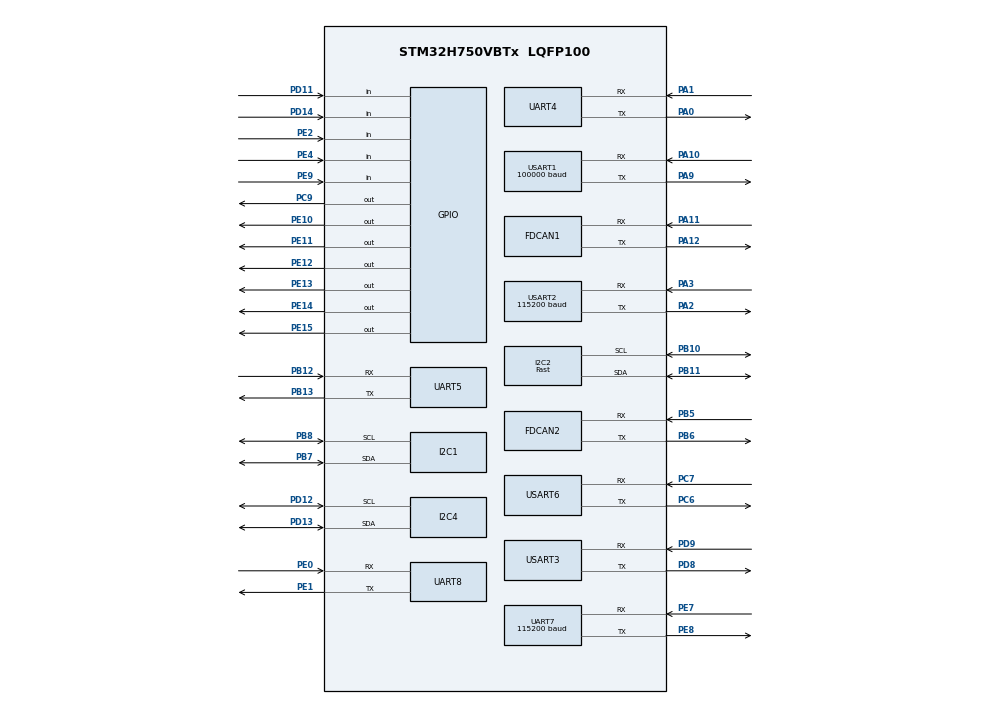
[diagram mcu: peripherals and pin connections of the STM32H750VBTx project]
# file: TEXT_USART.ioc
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Dma.Request0=USART1_RX
Dma.Request1=USART1_TX
Dma.Request10=UART7_RX
Dma.Request11=UART7_TX
Dma.Request12=UART8_RX
Dma.Request13=UART8_TX
Dma.Request14=USART6_TX
Dma.Request15=USART6_RX
Dma.Request2=USART2_RX
Dma.Request3=USART2_TX
Dma.Request4=USART3_RX
Dma.Request5=USART3_TX
Dma.Request6=UART4_RX
Dma.Request7=UART4_TX
Dma.Request8=UART5_RX
Dma.Request9=UART5_TX
Dma.UART4_RX.6.Direction=DMA_PERIPH_TO_MEMORY
Dma.UART4_RX.6.EventEnable=DISABLE
Dma.UART4_RX.6.FIFOMode=DMA_FIFOMODE_DISABLE
Dma.UART4_RX.6.Instance=DMA2_Stream0
Dma.UART4_RX.6.MemDataAlignment=DMA_MDATAALIGN_BYTE
Dma.UART4_RX.6.MemInc=DMA_MINC_ENABLE
Dma.UART4_RX.6.Mode=DMA_NORMAL
Dma.UART4_RX.6.PeriphDataAlignment=DMA_PDATAALIGN_BYTE
Dma.UART4_RX.6.PeriphInc=DMA_PINC_DISABLE
Dma.UART4_RX.6.Polarity=HAL_DMAMUX_REQ_GEN_RISING
Dma.UART4_RX.6.Priority=DMA_PRIORITY_LOW
Dma.UART4_RX.6.RequestNumber=1
Dma.UART4_RX.6.SignalID=NONE
Dma.UART4_RX.6.SyncEnable=DISABLE
Dma.UART4_RX.6.SyncPolarity=HAL_DMAMUX_SYNC_NO_EVENT
Dma.UART4_RX.6.SyncRequestNumber=1
Dma.UART4_RX.6.SyncSignalID=NONE
Dma.UART4_TX.7.Direction=DMA_MEMORY_TO_PERIPH
Dma.UART4_TX.7.EventEnable=DISABLE
Dma.UART4_TX.7.FIFOMode=DMA_FIFOMODE_DISABLE
Dma.UART4_TX.7.Instance=DMA2_Stream1
Dma.UART4_TX.7.MemDataAlignment=DMA_MDATAALIGN_BYTE
Dma.UART4_TX.7.MemInc=DMA_MINC_ENABLE
Dma.UART4_TX.7.Mode=DMA_NORMAL
Dma.UART4_TX.7.PeriphDataAlignment=DMA_PDATAALIGN_BYTE
Dma.UART4_TX.7.PeriphInc=DMA_PINC_DISABLE
Dma.UART4_TX.7.Polarity=HAL_DMAMUX_REQ_GEN_RISING
Dma.UART4_TX.7.Priority=DMA_PRIORITY_LOW
Dma.UART4_TX.7.RequestNumber=1
Dma.UART4_TX.7.SignalID=NONE
Dma.UART4_TX.7.SyncEnable=DISABLE
Dma.UART4_TX.7.SyncPolarity=HAL_DMAMUX_SYNC_NO_EVENT
Dma.UART4_TX.7.SyncRequestNumber=1
Dma.UART4_TX.7.SyncSignalID=NONE
Dma.UART5_RX.8.Direction=DMA_PERIPH_TO_MEMORY
Dma.UART5_RX.8.EventEnable=DISABLE
Dma.UART5_RX.8.FIFOMode=DMA_FIFOMODE_DISABLE
Dma.UART5_RX.8.Instance=DMA2_Stream3
Dma.UART5_RX.8.MemDataAlignment=DMA_MDATAALIGN_BYTE
Dma.UART5_RX.8.MemInc=DMA_MINC_ENABLE
Dma.UART5_RX.8.Mode=DMA_NORMAL
Dma.UART5_RX.8.PeriphDataAlignment=DMA_PDATAALIGN_BYTE
Dma.UART5_RX.8.PeriphInc=DMA_PINC_DISABLE
Dma.UART5_RX.8.Polarity=HAL_DMAMUX_REQ_GEN_RISING
Dma.UART5_RX.8.Priority=DMA_PRIORITY_LOW
Dma.UART5_RX.8.RequestNumber=1
Dma.UART5_RX.8.SignalID=NONE
Dma.UART5_RX.8.SyncEnable=DISABLE
Dma.UART5_RX.8.SyncPolarity=HAL_DMAMUX_SYNC_NO_EVENT
Dma.UART5_RX.8.SyncRequestNumber=1
Dma.UART5_RX.8.SyncSignalID=NONE
Dma.UART5_TX.9.Direction=DMA_MEMORY_TO_PERIPH
Dma.UART5_TX.9.EventEnable=DISABLE
Dma.UART5_TX.9.FIFOMode=DMA_FIFOMODE_DISABLE
Dma.UART5_TX.9.Instance=DMA2_Stream4
Dma.UART5_TX.9.MemDataAlignment=DMA_MDATAALIGN_BYTE
Dma.UART5_TX.9.MemInc=DMA_MINC_ENABLE
Dma.UART5_TX.9.Mode=DMA_NORMAL
Dma.UART5_TX.9.PeriphDataAlignment=DMA_PDATAALIGN_BYTE
Dma.UART5_TX.9.PeriphInc=DMA_PINC_DISABLE
Dma.UART5_TX.9.Polarity=HAL_DMAMUX_REQ_GEN_RISING
Dma.UART5_TX.9.Priority=DMA_PRIORITY_LOW
Dma.UART5_TX.9.RequestNumber=1
Dma.UART5_TX.9.SignalID=NONE
Dma.UART5_TX.9.SyncEnable=DISABLE
Dma.UART5_TX.9.SyncPolarity=HAL_DMAMUX_SYNC_NO_EVENT
Dma.UART5_TX.9.SyncRequestNumber=1
Dma.UART5_TX.9.SyncSignalID=NONE
Dma.UART7_RX.10.Direction=DMA_PERIPH_TO_MEMORY
Dma.UART7_RX.10.EventEnable=DISABLE
Dma.UART7_RX.10.FIFOMode=DMA_FIFOMODE_DISABLE
Dma.UART7_RX.10.Instance=DMA2_Stream6
Dma.UART7_RX.10.MemDataAlignment=DMA_MDATAALIGN_BYTE
Dma.UART7_RX.10.MemInc=DMA_MINC_ENABLE
Dma.UART7_RX.10.Mode=DMA_NORMAL
Dma.UART7_RX.10.PeriphDataAlignment=DMA_PDATAALIGN_BYTE
Dma.UART7_RX.10.PeriphInc=DMA_PINC_DISABLE
Dma.UART7_RX.10.Polarity=HAL_DMAMUX_REQ_GEN_RISING
Dma.UART7_RX.10.Priority=DMA_PRIORITY_LOW
Dma.UART7_RX.10.RequestNumber=1
Dma.UART7_RX.10.SignalID=NONE
Dma.UART7_RX.10.SyncEnable=DISABLE
Dma.UART7_RX.10.SyncPolarity=HAL_DMAMUX_SYNC_NO_EVENT
Dma.UART7_RX.10.SyncRequestNumber=1
Dma.UART7_RX.10.SyncSignalID=NONE
Dma.UART7_TX.11.Direction=DMA_MEMORY_TO_PERIPH
Dma.UART7_TX.11.EventEnable=DISABLE
Dma.UART7_TX.11.FIFOMode=DMA_FIFOMODE_DISABLE
Dma.UART7_TX.11.Instance=DMA2_Stream2
Dma.UART7_TX.11.MemDataAlignment=DMA_MDATAALIGN_BYTE
Dma.UART7_TX.11.MemInc=DMA_MINC_ENABLE
Dma.UART7_TX.11.Mode=DMA_NORMAL
Dma.UART7_TX.11.PeriphDataAlignment=DMA_PDATAALIGN_BYTE
Dma.UART7_TX.11.PeriphInc=DMA_PINC_DISABLE
Dma.UART7_TX.11.Polarity=HAL_DMAMUX_REQ_GEN_RISING
Dma.UART7_TX.11.Priority=DMA_PRIORITY_LOW
Dma.UART7_TX.11.RequestNumber=1
Dma.UART7_TX.11.SignalID=NONE
Dma.UART7_TX.11.SyncEnable=DISABLE
Dma.UART7_TX.11.SyncPolarity=HAL_DMAMUX_SYNC_NO_EVENT
Dma.UART7_TX.11.SyncRequestNumber=1
Dma.UART7_TX.11.SyncSignalID=NONE
Dma.UART8_RX.12.Direction=DMA_PERIPH_TO_MEMORY
Dma.UART8_RX.12.EventEnable=DISABLE
Dma.UART8_RX.12.FIFOMode=DMA_FIFOMODE_DISABLE
Dma.UART8_RX.12.Instance=DMA1_Stream5
Dma.UART8_RX.12.MemDataAlignment=DMA_MDATAALIGN_BYTE
Dma.UART8_RX.12.MemInc=DMA_MINC_ENABLE
Dma.UART8_RX.12.Mode=DMA_NORMAL
Dma.UART8_RX.12.PeriphDataAlignment=DMA_PDATAALIGN_BYTE
Dma.UART8_RX.12.PeriphInc=DMA_PINC_DISABLE
Dma.UART8_RX.12.Polarity=HAL_DMAMUX_REQ_GEN_RISING
Dma.UART8_RX.12.Priority=DMA_PRIORITY_LOW
Dma.UART8_RX.12.RequestNumber=1
Dma.UART8_RX.12.SignalID=NONE
Dma.UART8_RX.12.SyncEnable=DISABLE
Dma.UART8_RX.12.SyncPolarity=HAL_DMAMUX_SYNC_NO_EVENT
Dma.UART8_RX.12.SyncRequestNumber=1
Dma.UART8_RX.12.SyncSignalID=NONE
Dma.UART8_TX.13.Direction=DMA_MEMORY_TO_PERIPH
Dma.UART8_TX.13.EventEnable=DISABLE
Dma.UART8_TX.13.FIFOMode=DMA_FIFOMODE_DISABLE
Dma.UART8_TX.13.Instance=DMA2_Stream5
Dma.UART8_TX.13.MemDataAlignment=DMA_MDATAALIGN_BYTE
Dma.UART8_TX.13.MemInc=DMA_MINC_ENABLE
Dma.UART8_TX.13.Mode=DMA_NORMAL
Dma.UART8_TX.13.PeriphDataAlignment=DMA_PDATAALIGN_BYTE
Dma.UART8_TX.13.PeriphInc=DMA_PINC_DISABLE
Dma.UART8_TX.13.Polarity=HAL_DMAMUX_REQ_GEN_RISING
Dma.UART8_TX.13.Priority=DMA_PRIORITY_LOW
Dma.UART8_TX.13.RequestNumber=1
Dma.UART8_TX.13.SignalID=NONE
Dma.UART8_TX.13.SyncEnable=DISABLE
Dma.UART8_TX.13.SyncPolarity=HAL_DMAMUX_SYNC_NO_EVENT
Dma.UART8_TX.13.SyncRequestNumber=1
Dma.UART8_TX.13.SyncSignalID=NONE
Dma.USART1_RX.0.Direction=DMA_PERIPH_TO_MEMORY
Dma.USART1_RX.0.EventEnable=DISABLE
Dma.USART1_RX.0.FIFOMode=DMA_FIFOMODE_DISABLE
Dma.USART1_RX.0.Instance=DMA1_Stream0
Dma.USART1_RX.0.MemDataAlignment=DMA_MDATAALIGN_BYTE
Dma.USART1_RX.0.MemInc=DMA_MINC_ENABLE
Dma.USART1_RX.0.Mode=DMA_NORMAL
Dma.USART1_RX.0.PeriphDataAlignment=DMA_PDATAALIGN_BYTE
Dma.USART1_RX.0.PeriphInc=DMA_PINC_DISABLE
Dma.USART1_RX.0.Polarity=HAL_DMAMUX_REQ_GEN_RISING
Dma.USART1_RX.0.Priority=DMA_PRIORITY_HIGH
Dma.USART1_RX.0.RequestNumber=1
Dma.USART1_RX.0.SignalID=NONE
Dma.USART1_RX.0.SyncEnable=DISABLE
Dma.USART1_RX.0.SyncPolarity=HAL_DMAMUX_SYNC_NO_EVENT
Dma.USART1_RX.0.SyncRequestNumber=1
Dma.USART1_RX.0.SyncSignalID=NONE
Dma.USART1_TX.1.Direction=DMA_MEMORY_TO_PERIPH
Dma.USART1_TX.1.EventEnable=DISABLE
Dma.USART1_TX.1.FIFOMode=DMA_FIFOMODE_DISABLE
Dma.USART1_TX.1.Instance=DMA1_Stream6
Dma.USART1_TX.1.MemDataAlignment=DMA_MDATAALIGN_BYTE
Dma.USART1_TX.1.MemInc=DMA_MINC_ENABLE
Dma.USART1_TX.1.Mode=DMA_NORMAL
Dma.USART1_TX.1.PeriphDataAlignment=DMA_PDATAALIGN_BYTE
Dma.USART1_TX.1.PeriphInc=DMA_PINC_DISABLE
Dma.USART1_TX.1.Polarity=HAL_DMAMUX_REQ_GEN_RISING
Dma.USART1_TX.1.Priority=DMA_PRIORITY_HIGH
Dma.USART1_TX.1.RequestNumber=1
Dma.USART1_TX.1.SignalID=NONE
Dma.USART1_TX.1.SyncEnable=DISABLE
Dma.USART1_TX.1.SyncPolarity=HAL_DMAMUX_SYNC_NO_EVENT
Dma.USART1_TX.1.SyncRequestNumber=1
Dma.USART1_TX.1.SyncSignalID=NONE
Dma.USART2_RX.2.Direction=DMA_PERIPH_TO_MEMORY
Dma.USART2_RX.2.EventEnable=DISABLE
Dma.USART2_RX.2.FIFOMode=DMA_FIFOMODE_DISABLE
Dma.USART2_RX.2.Instance=DMA1_Stream4
Dma.USART2_RX.2.MemDataAlignment=DMA_MDATAALIGN_BYTE
Dma.USART2_RX.2.MemInc=DMA_MINC_ENABLE
Dma.USART2_RX.2.Mode=DMA_NORMAL
Dma.USART2_RX.2.PeriphDataAlignment=DMA_PDATAALIGN_BYTE
Dma.USART2_RX.2.PeriphInc=DMA_PINC_DISABLE
Dma.USART2_RX.2.Polarity=HAL_DMAMUX_REQ_GEN_RISING
Dma.USART2_RX.2.Priority=DMA_PRIORITY_LOW
Dma.USART2_RX.2.RequestNumber=1
Dma.USART2_RX.2.SignalID=NONE
Dma.USART2_RX.2.SyncEnable=DISABLE
Dma.USART2_RX.2.SyncPolarity=HAL_DMAMUX_SYNC_NO_EVENT
Dma.USART2_RX.2.SyncRequestNumber=1
Dma.USART2_RX.2.SyncSignalID=NONE
Dma.USART2_TX.3.Direction=DMA_MEMORY_TO_PERIPH
Dma.USART2_TX.3.EventEnable=DISABLE
Dma.USART2_TX.3.FIFOMode=DMA_FIFOMODE_DISABLE
Dma.USART2_TX.3.Instance=DMA1_Stream3
Dma.USART2_TX.3.MemDataAlignment=DMA_MDATAALIGN_BYTE
Dma.USART2_TX.3.MemInc=DMA_MINC_ENABLE
Dma.USART2_TX.3.Mode=DMA_NORMAL
Dma.USART2_TX.3.PeriphDataAlignment=DMA_PDATAALIGN_BYTE
Dma.USART2_TX.3.PeriphInc=DMA_PINC_DISABLE
Dma.USART2_TX.3.Polarity=HAL_DMAMUX_REQ_GEN_RISING
Dma.USART2_TX.3.Priority=DMA_PRIORITY_LOW
Dma.USART2_TX.3.RequestNumber=1
Dma.USART2_TX.3.SignalID=NONE
Dma.USART2_TX.3.SyncEnable=DISABLE
Dma.USART2_TX.3.SyncPolarity=HAL_DMAMUX_SYNC_NO_EVENT
Dma.USART2_TX.3.SyncRequestNumber=1
Dma.USART2_TX.3.SyncSignalID=NONE
Dma.USART3_RX.4.Direction=DMA_PERIPH_TO_MEMORY
Dma.USART3_RX.4.EventEnable=DISABLE
Dma.USART3_RX.4.FIFOMode=DMA_FIFOMODE_DISABLE
Dma.USART3_RX.4.Instance=DMA1_Stream1
Dma.USART3_RX.4.MemDataAlignment=DMA_MDATAALIGN_BYTE
Dma.USART3_RX.4.MemInc=DMA_MINC_ENABLE
Dma.USART3_RX.4.Mode=DMA_NORMAL
Dma.USART3_RX.4.PeriphDataAlignment=DMA_PDATAALIGN_BYTE
Dma.USART3_RX.4.PeriphInc=DMA_PINC_DISABLE
Dma.USART3_RX.4.Polarity=HAL_DMAMUX_REQ_GEN_RISING
Dma.USART3_RX.4.Priority=DMA_PRIORITY_LOW
Dma.USART3_RX.4.RequestNumber=1
Dma.USART3_RX.4.SignalID=NONE
Dma.USART3_RX.4.SyncEnable=DISABLE
Dma.USART3_RX.4.SyncPolarity=HAL_DMAMUX_SYNC_NO_EVENT
Dma.USART3_RX.4.SyncRequestNumber=1
Dma.USART3_RX.4.SyncSignalID=NONE
Dma.USART3_TX.5.Direction=DMA_MEMORY_TO_PERIPH
Dma.USART3_TX.5.EventEnable=DISABLE
Dma.USART3_TX.5.FIFOMode=DMA_FIFOMODE_DISABLE
Dma.USART3_TX.5.Instance=DMA1_Stream2
Dma.USART3_TX.5.MemDataAlignment=DMA_MDATAALIGN_BYTE
Dma.USART3_TX.5.MemInc=DMA_MINC_ENABLE
Dma.USART3_TX.5.Mode=DMA_NORMAL
Dma.USART3_TX.5.PeriphDataAlignment=DMA_PDATAALIGN_BYTE
Dma.USART3_TX.5.PeriphInc=DMA_PINC_DISABLE
Dma.USART3_TX.5.Polarity=HAL_DMAMUX_REQ_GEN_RISING
Dma.USART3_TX.5.Priority=DMA_PRIORITY_LOW
Dma.USART3_TX.5.RequestNumber=1
Dma.USART3_TX.5.SignalID=NONE
Dma.USART3_TX.5.SyncEnable=DISABLE
Dma.USART3_TX.5.SyncPolarity=HAL_DMAMUX_SYNC_NO_EVENT
Dma.USART3_TX.5.SyncRequestNumber=1
Dma.USART3_TX.5.SyncSignalID=NONE
Dma.USART6_RX.15.Direction=DMA_PERIPH_TO_MEMORY
Dma.USART6_RX.15.EventEnable=DISABLE
Dma.USART6_RX.15.FIFOMode=DMA_FIFOMODE_DISABLE
Dma.USART6_RX.15.Instance=DMA2_Stream7
Dma.USART6_RX.15.MemDataAlignment=DMA_MDATAALIGN_BYTE
Dma.USART6_RX.15.MemInc=DMA_MINC_ENABLE
Dma.USART6_RX.15.Mode=DMA_NORMAL
Dma.USART6_RX.15.PeriphDataAlignment=DMA_PDATAALIGN_BYTE
Dma.USART6_RX.15.PeriphInc=DMA_PINC_DISABLE
Dma.USART6_RX.15.Polarity=HAL_DMAMUX_REQ_GEN_RISING
Dma.USART6_RX.15.Priority=DMA_PRIORITY_LOW
Dma.USART6_RX.15.RequestNumber=1
Dma.USART6_RX.15.SignalID=NONE
Dma.USART6_RX.15.SyncEnable=DISABLE
Dma.USART6_RX.15.SyncPolarity=HAL_DMAMUX_SYNC_NO_EVENT
Dma.USART6_RX.15.SyncRequestNumber=1
Dma.USART6_RX.15.SyncSignalID=NONE
Dma.USART6_TX.14.Direction=DMA_MEMORY_TO_PERIPH
Dma.USART6_TX.14.EventEnable=DISABLE
Dma.USART6_TX.14.FIFOMode=DMA_FIFOMODE_DISABLE
Dma.USART6_TX.14.Instance=DMA1_Stream7
Dma.USART6_TX.14.MemDataAlignment=DMA_MDATAALIGN_BYTE
Dma.USART6_TX.14.MemInc=DMA_MINC_ENABLE
Dma.USART6_TX.14.Mode=DMA_NORMAL
Dma.USART6_TX.14.PeriphDataAlignment=DMA_PDATAALIGN_BYTE
Dma.USART6_TX.14.PeriphInc=DMA_PINC_DISABLE
Dma.USART6_TX.14.Polarity=HAL_DMAMUX_REQ_GEN_RISING
Dma.USART6_TX.14.Priority=DMA_PRIORITY_LOW
Dma.USART6_TX.14.RequestNumber=1
Dma.USART6_TX.14.SignalID=NONE
Dma.USART6_TX.14.SyncEnable=DISABLE
Dma.USART6_TX.14.SyncPolarity=HAL_DMAMUX_SYNC_NO_EVENT
Dma.USART6_TX.14.SyncRequestNumber=1
Dma.USART6_TX.14.SyncSignalID=NONE
FDCAN1.CalculateBaudRateNominal=1000000
FDCAN1.CalculateTimeQuantumNominal=25.0
FDCAN1.NominalPrescaler=1
FDCAN1.NominalSyncJumpWidth=8
FDCAN1.NominalTimeSeg1=31
FDCAN1.NominalTimeSeg2=8
FDCAN1.RxFifo0ElmtsNbr=32
FDCAN1.TxFifoQueueElmtsNbr=10
FDCAN2.CalculateBaudRateNominal=1000000
FDCAN2.CalculateTimeQuantumNominal=25.0
FDCAN2.MessageRAMOffset=1280
FDCAN2.NominalPrescaler=1
FDCAN2.NominalSyncJumpWidth=8
FDCAN2.NominalTimeSeg1=31
FDCAN2.NominalTimeSeg2=8
FDCAN2.RxFifo0ElmtsNbr=32
FDCAN2.TxFifoQueueElmtsNbr=10
I2C1.Timing=0x307075B1
I2C2.I2C_Speed_Mode=I2C_Fast
I2C2.Timing=0x00B03FDB
I2C4.Timing=0x307075B1
Mcu.Family=STM32H7
Mcu.Name=STM32H750VBTx
Mcu.Package=LQFP100
NVIC.DMA1_Stream0_IRQn=true\:1\:0\:true\:false\:true\:false\:true\:true
NVIC.DMA1_Stream1_IRQn=true\:0\:0\:false\:false\:true\:false\:true\:true
NVIC.DMA1_Stream2_IRQn=true\:0\:0\:false\:false\:true\:false\:true\:true
NVIC.DMA1_Stream3_IRQn=true\:0\:0\:false\:false\:true\:false\:true\:true
NVIC.DMA1_Stream4_IRQn=true\:0\:0\:false\:false\:true\:false\:true\:true
NVIC.DMA1_Stream5_IRQn=true\:0\:0\:false\:false\:true\:false\:true\:true
NVIC.DMA1_Stream6_IRQn=true\:0\:0\:false\:false\:true\:false\:true\:true
NVIC.DMA1_Stream7_IRQn=true\:0\:0\:false\:false\:true\:false\:true\:true
NVIC.DMA2_Stream0_IRQn=true\:0\:0\:false\:false\:true\:false\:true\:true
NVIC.DMA2_Stream1_IRQn=true\:0\:0\:false\:false\:true\:false\:true\:true
NVIC.DMA2_Stream2_IRQn=true\:0\:0\:false\:false\:true\:false\:true\:true
NVIC.DMA2_Stream3_IRQn=true\:0\:0\:false\:false\:true\:false\:true\:true
NVIC.DMA2_Stream4_IRQn=true\:0\:0\:false\:false\:true\:false\:true\:true
NVIC.DMA2_Stream5_IRQn=true\:0\:0\:false\:false\:true\:false\:true\:true
NVIC.DMA2_Stream6_IRQn=true\:0\:0\:false\:false\:true\:false\:true\:true
NVIC.DMA2_Stream7_IRQn=true\:0\:0\:false\:false\:true\:false\:true\:true
NVIC.FDCAN1_IT0_IRQn=true\:2\:0\:true\:false\:true\:true\:true\:true
NVIC.FDCAN2_IT0_IRQn=true\:1\:0\:true\:false\:true\:true\:true\:true
NVIC.PriorityGroup=NVIC_PRIORITYGROUP_4
NVIC.TIM8_TRG_COM_TIM14_IRQn=true\:3\:0\:true\:false\:true\:true\:true\:true
NVIC.TIM8_UP_TIM13_IRQn=true\:0\:0\:false\:false\:true\:true\:true\:true
NVIC.UART4_IRQn=true\:0\:0\:false\:false\:true\:true\:true\:true
NVIC.UART5_IRQn=true\:0\:0\:false\:false\:true\:true\:true\:true
NVIC.UART7_IRQn=true\:0\:0\:false\:false\:true\:true\:true\:true
NVIC.UART8_IRQn=true\:0\:0\:false\:false\:true\:true\:true\:true
NVIC.USART1_IRQn=true\:1\:0\:true\:false\:true\:true\:true\:true
NVIC.USART2_IRQn=true\:0\:0\:false\:false\:true\:true\:true\:true
NVIC.USART3_IRQn=true\:0\:0\:false\:false\:true\:true\:true\:true
NVIC.USART6_IRQn=true\:0\:0\:false\:false\:true\:true\:true\:true
PA0.Mode=Asynchronous
PA0.Signal=UART4_TX
PA1.Mode=Asynchronous
PA1.Signal=UART4_RX
PA10.GPIO_PuPd=GPIO_PULLUP
PA10.Mode=Asynchronous
PA10.Signal=USART1_RX
PA11.Mode=FDCAN_Activate
PA11.Signal=FDCAN1_RX
PA12.Mode=FDCAN_Activate
PA12.Signal=FDCAN1_TX
PA2.Mode=Asynchronous
PA2.Signal=USART2_TX
PA3.Mode=Asynchronous
PA3.Signal=USART2_RX
PA9.GPIO_PuPd=GPIO_PULLUP
PA9.Mode=Asynchronous
PA9.Signal=USART1_TX
PB10.Mode=I2C
PB10.Signal=I2C2_SCL
PB11.Mode=I2C
PB11.Signal=I2C2_SDA
PB12.Mode=Asynchronous
PB12.Signal=UART5_RX
PB13.Mode=Asynchronous
PB13.Signal=UART5_TX
PB5.Mode=FDCAN_Activate
PB5.Signal=FDCAN2_RX
PB6.Mode=FDCAN_Activate
PB6.Signal=FDCAN2_TX
PB7.Mode=I2C
PB7.Signal=I2C1_SDA
PB8.Mode=I2C
PB8.Signal=I2C1_SCL
PC6.Mode=Asynchronous
PC6.Signal=USART6_TX
PC7.Mode=Asynchronous
PC7.Signal=USART6_RX
PC9.Signal=GPIO_Output
PD11.GPIO_PuPd=GPIO_NOPULL
PD11.Signal=GPIO_Input
PD12.Mode=I2C
PD12.Signal=I2C4_SCL
PD13.Mode=I2C
PD13.Signal=I2C4_SDA
PD14.GPIO_PuPd=GPIO_PULLDOWN
PD14.Signal=GPIO_Input
PD15.Signal=S_TIM4_CH4
PD8.Mode=Asynchronous
PD8.Signal=USART3_TX
PD9.Mode=Asynchronous
PD9.Signal=USART3_RX
PE0.Mode=Asynchronous
PE0.Signal=UART8_RX
PE1.Mode=Asynchronous
PE1.Signal=UART8_TX
PE10.Signal=GPIO_Output
PE11.Signal=GPIO_Output
PE12.Signal=GPIO_Output
PE13.Signal=GPIO_Output
PE14.Signal=GPIO_Output
PE15.Signal=GPIO_Output
PE2.GPIO_PuPd=GPIO_PULLDOWN
PE2.Signal=GPIO_Input
PE4.GPIO_PuPd=GPIO_PULLUP
PE4.Signal=GPIO_Input
PE7.Mode=Asynchronous
PE7.Signal=UART7_RX
PE8.Mode=Asynchronous
PE8.Signal=UART7_TX
PE9.GPIO_PuPd=GPIO_PULLDOWN
PE9.Signal=GPIO_Input
PH0-OSC_IN\ (PH0).Mode=HSE-External-Oscillator
PH0-OSC_IN\ (PH0).Signal=RCC_OSC_IN
PH1-OSC_OUT\ (PH1).Mode=HSE-External-Oscillator
PH1-OSC_OUT\ (PH1).Signal=RCC_OSC_OUT
ProjectManager.HeapSize=0x1400
ProjectManager.StackSize=0x400
ProjectManager.TargetToolchain=MDK-ARM V5
RCC.ADCFreq_Value=16125000
RCC.APB1Freq_Value=120000000
RCC.APB2Freq_Value=120000000
RCC.APB3Freq_Value=120000000
RCC.APB4Freq_Value=120000000
RCC.CortexFreq_Value=480000000
RCC.D1PPRE=RCC_APB3_DIV2
RCC.D2PPRE1=RCC_APB1_DIV2
RCC.D2PPRE2=RCC_APB2_DIV2
RCC.D3PPRE=RCC_APB4_DIV2
RCC.DIVM1=1
RCC.DIVN1=120
RCC.DIVQ1=24
RCC.HCLKFreq_Value=240000000
RCC.HPRE=RCC_HCLK_DIV2
RCC.HSE_VALUE=8000000
RCC.PLL2FRACN=0
RCC.PLL3FRACN=0
RCC.PLLFRACN=0
RCC.PLLSourceVirtual=RCC_PLLSOURCE_HSE
RCC.SYSCLKFreq_VALUE=480000000
RCC.SYSCLKSource=RCC_SYSCLKSOURCE_PLLCLK
RCC.USBFreq_Value=40000000
SH.S_TIM4_CH4.0=TIM4_CH4
TIM13.Period=99
TIM13.Prescaler=239
TIM14.Period=999
TIM14.Prescaler=239
UART7.BaudRate=115200
USART1.BaudRate=100000
USART1.Parity=PARITY_EVEN
USART1.VirtualMode-Asynchronous=VM_ASYNC
USART1.WordLength=WORDLENGTH_9B
USART2.BaudRate=115200
USART2.Parity=PARITY_NONE
USART2.VirtualMode-Asynchronous=VM_ASYNC
USART2.WordLength=WORDLENGTH_8B
USART3.VirtualMode-Asynchronous=VM_ASYNC
USART6.VirtualMode=VM_ASYNC
VP_MEMORYMAP_VS_MEMORYMAP.Mode=CurAppReg
VP_TIM13_VS_ClockSourceINT.Mode=Enable_Timer
VP_TIM14_VS_ClockSourceINT.Mode=Enable_Timer
board=custom

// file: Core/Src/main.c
/* USER CODE BEGIN Header */
/**
  ******************************************************************************
  * @file           : main.c
  * @brief          : Main program body
  ******************************************************************************
  * @attention
  *
  * <h2><center>&copy; Copyright (c) 2022 STMicroelectronics.
  * All rights reserved.</center></h2>
  *
  * This software component is licensed by ST under BSD 3-Clause license,
  * the "License"; You may not use this file except in compliance with the
  * License. You may obtain a copy of the License at:
  *                        opensource.org/licenses/BSD-3-Clause
  *
  ******************************************************************************
  */
/* USER CODE END Header */
#include "main.h"
#include "dma.h"
#include "fdcan.h"
#include "i2c.h"
#include "memorymap.h"
#include "tim.h"
#include "usart.h"
#include "gpio.h"

/* USER CODE BEGIN Includes */
#include "hardware_config.h"
/* USER CODE END Includes */

void SystemClock_Config(void);

int main(void)
{

  /* MCU Configuration--------------------------------------------------------*/

  /* Reset of all peripherals, Initializes the Flash interface and the Systick. */
  HAL_Init();

  /* Configure the system clock */
  SystemClock_Config();

  /* Initialize all configured peripherals */
  MX_GPIO_Init();
  MX_DMA_Init();
  MX_USART1_UART_Init();
  MX_FDCAN1_Init();
  MX_FDCAN2_Init();
  MX_TIM14_Init();
  MX_USART2_UART_Init();
  MX_USART3_UART_Init();
  MX_UART4_Init();
  MX_UART5_Init();
  MX_USART6_UART_Init();
  MX_UART7_Init();
  MX_UART8_Init();
  MX_I2C1_Init();
  MX_I2C2_Init();
  MX_I2C4_Init();
  MX_TIM13_Init();
  /* USER CODE BEGIN 2 */
	HardwareConfig();
//  HAL_UART_Receive_DMA(&huart1,);

//	__weak void HAL_UART_RxCpltCallback(UART_HandleTypeDef *huart)
  /* USER CODE END 2 */

  /* Infinite loop */
  while (1)
  {

  }
}

void SystemClock_Config(void)
{
  RCC_OscInitTypeDef RCC_OscInitStruct = {0};
  RCC_ClkInitTypeDef RCC_ClkInitStruct = {0};

  /** Supply configuration update enable
  */
  HAL_PWREx_ConfigSupply(PWR_LDO_SUPPLY);

  /** Configure the main internal regulator output voltage
  */
  __HAL_PWR_VOLTAGESCALING_CONFIG(PWR_REGULATOR_VOLTAGE_SCALE1);

  while(!__HAL_PWR_GET_FLAG(PWR_FLAG_VOSRDY)) {}

  __HAL_RCC_SYSCFG_CLK_ENABLE();
  __HAL_PWR_VOLTAGESCALING_CONFIG(PWR_REGULATOR_VOLTAGE_SCALE0);

  while(!__HAL_PWR_GET_FLAG(PWR_FLAG_VOSRDY)) {}

  /** Initializes the RCC Oscillators according to the specified parameters
  * in the RCC_OscInitTypeDef structure.
  */
  RCC_OscInitStruct.OscillatorType = RCC_OSCILLATORTYPE_HSE;
  RCC_OscInitStruct.HSEState = RCC_HSE_ON;
  RCC_OscInitStruct.PLL.PLLState = RCC_PLL_ON;
  RCC_OscInitStruct.PLL.PLLSource = RCC_PLLSOURCE_HSE;
  RCC_OscInitStruct.PLL.PLLM = 1;
  RCC_OscInitStruct.PLL.PLLN = 120;
  RCC_OscInitStruct.PLL.PLLP = 2;
  RCC_OscInitStruct.PLL.PLLQ = 24;
  RCC_OscInitStruct.PLL.PLLR = 2;
  RCC_OscInitStruct.PLL.PLLRGE = RCC_PLL1VCIRANGE_3;
  RCC_OscInitStruct.PLL.PLLVCOSEL = RCC_PLL1VCOWIDE;
  RCC_OscInitStruct.PLL.PLLFRACN = 0;
  if (HAL_RCC_OscConfig(&RCC_OscInitStruct) != HAL_OK)
  {
    Error_Handler();
  }

  /** Initializes the CPU, AHB and APB buses clocks
  */
  RCC_ClkInitStruct.ClockType = RCC_CLOCKTYPE_HCLK|RCC_CLOCKTYPE_SYSCLK
                              |RCC_CLOCKTYPE_PCLK1|RCC_CLOCKTYPE_PCLK2
                              |RCC_CLOCKTYPE_D3PCLK1|RCC_CLOCKTYPE_D1PCLK1;
  RCC_ClkInitStruct.SYSCLKSource = RCC_SYSCLKSOURCE_PLLCLK;
  RCC_ClkInitStruct.SYSCLKDivider = RCC_SYSCLK_DIV1;
  RCC_ClkInitStruct.AHBCLKDivider = RCC_HCLK_DIV2;
  RCC_ClkInitStruct.APB3CLKDivider = RCC_APB3_DIV2;
  RCC_ClkInitStruct.APB1CLKDivider = RCC_APB1_DIV2;
  RCC_ClkInitStruct.APB2CLKDivider = RCC_APB2_DIV2;
  RCC_ClkInitStruct.APB4CLKDivider = RCC_APB4_DIV2;

  if (HAL_RCC_ClockConfig(&RCC_ClkInitStruct, FLASH_LATENCY_4) != HAL_OK)
  {
    Error_Handler();
  }
}

void Error_Handler(void)
{
  __disable_irq();
  while (1)
  {
  }
}
